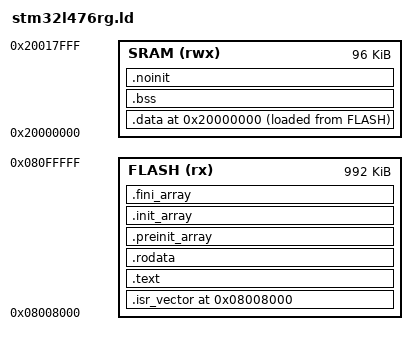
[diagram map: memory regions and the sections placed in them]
ENTRY(Reset_Handler)

/*
 * ============================================================
 * STM32L476RG MEMORY MAP
 * ============================================================
 *
 * Flash:
 *   0x08000000 - 0x08007FFF : Bootloader (32 KiB)
 *   0x08008000 - 0x080FFFFF : Application (992 KiB)
 *
 * SRAM:
 *   0x20000000 - 0x20017FFF : Application SRAM (96 KiB)
 *
 * ============================================================
 */

MEMORY
{
    FLASH (rx)  : ORIGIN = 0x08008000, LENGTH = 992K
    SRAM  (rwx) : ORIGIN = 0x20000000, LENGTH = 96K
}

SECTIONS
{
    /* Flash */
    . = ORIGIN(FLASH);

    /* Interrupt Vector Table */
    .isr_vector ALIGN(4) :
    {
        __isr_vector_start = .;

        KEEP(*(.isr_vector))
        KEEP(*(.isr_vector.*))

        __isr_vector_end = .;
    } > FLASH

    __isr_vector_size = ABSOLUTE(__isr_vector_end - __isr_vector_start);

    /*
     * --------------------------------------------------------
     * Application Header
     * --------------------------------------------------------
     *
     * Contains metadata such as:
     *
     *   magic
     *   version
     *   image size
     *   entry information
     *   CRC/hash
     *   etc.
     *
     */
/*
    .application_header ALIGN(16) :
    {
        __app_header_start = .;

        KEEP(*(.application_header))
        KEEP(*(.application_header.*))

        __app_header_end = .;
    } > FLASH

    __app_header_size = ABSOLUTE(__app_header_end - __app_header_start);
*/
    /*
     * --------------------------------------------------------
     * Application Signature
     * --------------------------------------------------------
     *
     * Reserved area for firmware authentication/signature.
     */
/*
    .application_signature ALIGN(16) :
    {
        __app_signature_start = .;

        KEEP(*(.application_signature))
        KEEP(*(.application_signature.*))

        __app_signature_end = .;
    } > FLASH

    __app_signature_size = ABSOLUTE(__app_signature_end - __app_signature_start);
*/

    /* Program Code */
    .text ALIGN(4) :
    {
        KEEP(*(.text))
        KEEP(*(.text.*))
        . = ALIGN(4);
    } > FLASH

    /* Ready-only data */
    .rodata ALIGN(4) :
    {
        KEEP(*(.rodata))
        KEEP(*(.rodata.*))
        . = ALIGN(4);
    } > FLASH


    /*
     * --------------------------------------------------------
     * C pre-initialization
     * --------------------------------------------------------
     *
     * Functions executed before normal C++ initialization.
     */
    .preinit_array ALIGN(4) :
    {
        PROVIDE_HIDDEN(__preinit_array_start = .);

        KEEP(*(.preinit_array))
        KEEP(*(.preinit_array.*))

        PROVIDE_HIDDEN(__preinit_array_end = .);

        . = ALIGN(4);
    } > FLASH


    /*
     * --------------------------------------------------------
     * C++ Static Initialization
     * --------------------------------------------------------
     *
     * Contains pointers to functions generated by the compiler
     * for global/static C++ object constructors.
     */

    .init_array ALIGN(4) :
    {
        PROVIDE_HIDDEN(__init_array_start = .);

        KEEP(*(.init_array))
        KEEP(*(.init_array.*))

        PROVIDE_HIDDEN(__init_array_end = .);

        . = ALIGN(4);
    } > FLASH


    /*
     * --------------------------------------------------------
     * C++ Static Destruction
     * --------------------------------------------------------
     *
     * Not normally used
     */

    .fini_array ALIGN(4) :
    {
        PROVIDE_HIDDEN(__fini_array_start = .);

        KEEP(*(.fini_array))
        KEEP(*(.fini_array.*))

        PROVIDE_HIDDEN(__fini_array_end = .);

        . = ALIGN(4);
    } > FLASH


    /*
     * SRAM
     */

    /*
     * --------------------------------------------------------
     * Initial Stack Pointer
     * --------------------------------------------------------
     *
     * Cortex-M starts with:
     *
     *   SP = _estack
     *
     * The stack grows downward.
     */

    _estack = ORIGIN(SRAM) + LENGTH(SRAM);


    /*
     * Start SRAM allocation.
     */

    . = ORIGIN(SRAM);


    /*
     * --------------------------------------------------------
     * Initialized Data
     * --------------------------------------------------------
     *
     * Example:
     *
     *   uint32_t counter = 123;
     *
     * The initial value is stored in FLASH and copied to SRAM
     * by Reset_Handler.
     *
     * FLASH:
     *   _sidata
     *
     * SRAM:
     *   _sdata ... _edata
     */

    .data ALIGN(4) :
    {
        _sdata = .;

        *(.data)
        *(.data.*)

        . = ALIGN(4);

        _edata = .;
    } > SRAM AT > FLASH


    /*
     * Address in FLASH containing the initial .data values.
     */

    _sidata = LOADADDR(.data);


    /*
     * --------------------------------------------------------
     * Zero-initialized Data
     * --------------------------------------------------------
     *
     * Example:
     *
     *   uint32_t counter;
     *
     * Reset_Handler clears this region to zero.
     */

    .bss ALIGN(4) :
    {
        _sbss = .;

        *(.bss)
        *(.bss.*)

        *(COMMON)

        . = ALIGN(4);

        _ebss = .;
    } > SRAM


    /*
     * --------------------------------------------------------
     * NOINIT
     * --------------------------------------------------------
     *
     * Variables in this section are NOT initialized by the
     * startup code.
     *
     * Useful for values that should survive a software reset.
     */

    .noinit ALIGN(4) :
    {
        _snoinit = .;

        *(.noinit)
        *(.noinit.*)

        . = ALIGN(4);

        _enoinit = .;
    } > SRAM


    /*
     * End of statically allocated SRAM.
     */

    _end = .;


    /*
     * ========================================================
     * Linker Assertions
     * ========================================================
     *
     * Detect memory overflow at link time instead of discovering
     * it later on the MCU.
     */

    ASSERT(
        _estack > _end,
        "ERROR: SRAM overflow"
    )

    ASSERT(
        __isr_vector_start == ORIGIN(FLASH),
        "ERROR: Vector table is not at application start"
    )


    /*
     * ========================================================
     * Discarded Sections
     * ========================================================
     */

    /DISCARD/ :
    {
        *(.ARM.exidx*)
        *(.gnu.linkonce.armexidx.*)
        *(.ARM.attributes)
        *(.comment)
        *(.debug_frame)
    }
}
